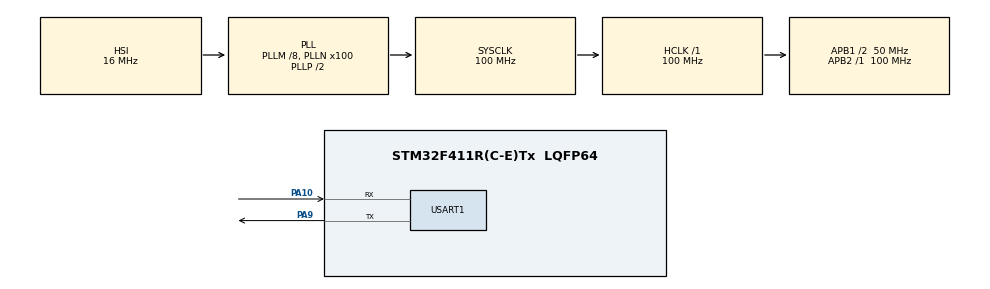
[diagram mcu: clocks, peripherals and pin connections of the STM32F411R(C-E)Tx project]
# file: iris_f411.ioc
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Mcu.Family=STM32F4
Mcu.Name=STM32F411R(C-E)Tx
Mcu.Package=LQFP64
NVIC.PriorityGroup=NVIC_PRIORITYGROUP_4
NVIC.USART1_IRQn=true\:0\:0\:false\:false\:true\:true\:true\:true
PA10.Mode=Asynchronous
PA10.Signal=USART1_RX
PA13.Mode=Serial_Wire
PA13.Signal=SYS_JTMS-SWDIO
PA14.Mode=Serial_Wire
PA14.Signal=SYS_JTCK-SWCLK
PA9.Mode=Asynchronous
PA9.Signal=USART1_TX
ProjectManager.HeapSize=0x800
ProjectManager.StackSize=0x800
ProjectManager.TargetToolchain=MDK-ARM V5.32
RCC.48MHZClocksFreq_Value=28571428.57142857
RCC.AHBFreq_Value=100000000
RCC.APB1CLKDivider=RCC_HCLK_DIV2
RCC.APB1Freq_Value=50000000
RCC.APB1TimFreq_Value=100000000
RCC.APB2Freq_Value=100000000
RCC.APB2TimFreq_Value=100000000
RCC.CortexFreq_Value=100000000
RCC.FLatency-AdvancedSettings=FLASH_LATENCY_3
RCC.HCLKFreq_Value=100000000
RCC.HSE_VALUE=25000000
RCC.HSI_VALUE=16000000
RCC.LSE_VALUE=32768
RCC.PLLM=8
RCC.PLLMUL=RCC_PLL_MUL9
RCC.PLLN=100
RCC.PLLQ=7
RCC.RCC_PLLsource_Clock_Source_FROM_HSE=RCC_HSE_PREDIV_DIV2
RCC.SYSCLKFreq_VALUE=100000000
RCC.SYSCLKSource=RCC_SYSCLKSOURCE_PLLCLK
RCC.SYSCLKSourceVirtual=RCC_SYSCLKSOURCE_PLLCLK
RCC.VCOOutputFreq_Value=200000000
STMicroelectronics.X-CUBE-AI.10.2.0.ActivationBufferSizeList=2052
STMicroelectronics.X-CUBE-AI.10.2.0.ActivationBuffers=pool0
STMicroelectronics.X-CUBE-AI.10.2.0.ActivationNames=pool0
STMicroelectronics.X-CUBE-AI.10.2.0.ActivationSizes=AI_NETWORK_DATA_ACTIVATION_1_SIZE
STMicroelectronics.X-CUBE-AI.10.2.0.ApplicationCcDeviceJjApplication=ApplicationTemplate
STMicroelectronics.X-CUBE-AI.10.2.0.HeapSize=0x800
STMicroelectronics.X-CUBE-AI.10.2.0.InternalRamActivationBufferMaxSize=AI_NETWORK_DATA_ACTIVATIONS_SIZE
STMicroelectronics.X-CUBE-AI.10.2.0.LatestDirectoryUsed-66b77b68632d567aa93bb05c56d0c70e0db3c44ed29e73d25cb62fc59ebfa969=D\:\\iris_stm32
STMicroelectronics.X-CUBE-AI.10.2.0.MaximumNumberOfInputLayer=1
STMicroelectronics.X-CUBE-AI.10.2.0.MaximumNumberOfOutputLayer=1
STMicroelectronics.X-CUBE-AI.10.2.0.MaximumSizeOfInputLayer=1
STMicroelectronics.X-CUBE-AI.10.2.0.MaximumSizeOfOutputLayer=1
STMicroelectronics.X-CUBE-AI.10.2.0.ModelActualCompression-66b77b68632d567aa93bb05c56d0c70e0db3c44ed29e73d25cb62fc59ebfa969=0.0
STMicroelectronics.X-CUBE-AI.10.2.0.ModelCompression-66b77b68632d567aa93bb05c56d0c70e0db3c44ed29e73d25cb62fc59ebfa969=None
STMicroelectronics.X-CUBE-AI.10.2.0.ModelFlashOccupation-66b77b68632d567aa93bb05c56d0c70e0db3c44ed29e73d25cb62fc59ebfa969=11440
STMicroelectronics.X-CUBE-AI.10.2.0.ModelHashList=66b77b68632d567aa93bb05c56d0c70e0db3c44ed29e73d25cb62fc59ebfa969
STMicroelectronics.X-CUBE-AI.10.2.0.ModelKind-66b77b68632d567aa93bb05c56d0c70e0db3c44ed29e73d25cb62fc59ebfa969=TFLITE
STMicroelectronics.X-CUBE-AI.10.2.0.ModelMacc-66b77b68632d567aa93bb05c56d0c70e0db3c44ed29e73d25cb62fc59ebfa969=200
STMicroelectronics.X-CUBE-AI.10.2.0.ModelName-66b77b68632d567aa93bb05c56d0c70e0db3c44ed29e73d25cb62fc59ebfa969=network
STMicroelectronics.X-CUBE-AI.10.2.0.ModelNameList=network
STMicroelectronics.X-CUBE-AI.10.2.0.ModelRamOccupation-66b77b68632d567aa93bb05c56d0c70e0db3c44ed29e73d25cb62fc59ebfa969=2052
STMicroelectronics.X-CUBE-AI.10.2.0.ModelStructureFile-66b77b68632d567aa93bb05c56d0c70e0db3c44ed29e73d25cb62fc59ebfa969=/D\:/iris_stm32/iris_model.tflite
STMicroelectronics.X-CUBE-AI.10.2.0.ModelType-66b77b68632d567aa93bb05c56d0c70e0db3c44ed29e73d25cb62fc59ebfa969=STM32Cube.AI MCU runtime
STMicroelectronics.X-CUBE-AI.10.2.0.ReadyForCodeGeneration=true
STMicroelectronics.X-CUBE-AI.10.2.0.StackSize=0x800
STMicroelectronics.X-CUBE-AI.10.2.0.WorkingBufferStartAddrList=0xFFFFFFFF
STMicroelectronics.X-CUBE-AI.10.2.0.XAaCUBEAaAICcArtificialOoIntelligenceJjCore=true
STMicroelectronics.X-CUBE-AI.10.2.0.copyWeightToRam=false
STMicroelectronics.X-CUBE-AI.10.2.0.customLayerConfigEnabled=false
STMicroelectronics.X-CUBE-AI.10.2.0.noOnnxIoTranspose=false
STMicroelectronics.X-CUBE-AI.10.2.0.useInputAllocation=true
STMicroelectronics.X-CUBE-AI.10.2.0.useOutputAllocation=true
USART1.VirtualMode=VM_ASYNC
VP_CRC_VS_CRC.Mode=CRC_Activate
VP_STMicroelectronics.X-CUBE-AI_VS_ArtificialOoIntelligenceJjXAaCUBEAaAI_10.2.0.Mode=ArtificialOoIntelligenceJjXAaCUBEAaAI
VP_STMicroelectronics.X-CUBE-AI_VS_DeviceJjApplication_10.2.0.Mode=DeviceJjApplication
board=custom

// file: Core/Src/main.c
/* USER CODE BEGIN Header */
/**
  ******************************************************************************
  * @file           : main.c
  * @brief          : Main program body
  ******************************************************************************
  * @attention
  *
  * Copyright (c) 2026 STMicroelectronics.
  * All rights reserved.
  *
  * This software is licensed under terms that can be found in the LICENSE file
  * in the root directory of this software component.
  * If no LICENSE file comes with this software, it is provided AS-IS.
  *
  ******************************************************************************
  */
/* USER CODE END Header */
#include "main.h"
#include "app_x-cube-ai.h"

/* USER CODE BEGIN Includes */
#include "iris_uart.h"
/* USER CODE END Includes */

CRC_HandleTypeDef hcrc;

UART_HandleTypeDef huart1;

void SystemClock_Config(void);
static void MX_GPIO_Init(void);
static void MX_CRC_Init(void);
static void MX_USART1_UART_Init(void);

int main(void)
{

  /* MCU Configuration--------------------------------------------------------*/

  /* Reset of all peripherals, Initializes the Flash interface and the Systick. */
  HAL_Init();

  /* Configure the system clock */
  SystemClock_Config();

  /* Initialize all configured peripherals */
  MX_GPIO_Init();
  MX_CRC_Init();
  MX_USART1_UART_Init();
  //MX_X_CUBE_AI_Init();
  /* USER CODE BEGIN 2 */
	IrisApp_Init();
  /* USER CODE END 2 */

  /* Infinite loop */
  while (1)
  {

  //MX_X_CUBE_AI_Process();
    /* USER CODE BEGIN 3 */
		IrisApp_Process();
  }
  /* USER CODE END 3 */
}

void SystemClock_Config(void)
{
  RCC_OscInitTypeDef RCC_OscInitStruct = {0};
  RCC_ClkInitTypeDef RCC_ClkInitStruct = {0};

  /** Configure the main internal regulator output voltage
  */
  __HAL_RCC_PWR_CLK_ENABLE();
  __HAL_PWR_VOLTAGESCALING_CONFIG(PWR_REGULATOR_VOLTAGE_SCALE1);

  /** Initializes the RCC Oscillators according to the specified parameters
  * in the RCC_OscInitTypeDef structure.
  */
  RCC_OscInitStruct.OscillatorType = RCC_OSCILLATORTYPE_HSI;
  RCC_OscInitStruct.HSIState = RCC_HSI_ON;
  RCC_OscInitStruct.HSICalibrationValue = RCC_HSICALIBRATION_DEFAULT;
  RCC_OscInitStruct.PLL.PLLState = RCC_PLL_ON;
  RCC_OscInitStruct.PLL.PLLSource = RCC_PLLSOURCE_HSI;
  RCC_OscInitStruct.PLL.PLLM = 8;
  RCC_OscInitStruct.PLL.PLLN = 100;
  RCC_OscInitStruct.PLL.PLLP = RCC_PLLP_DIV2;
  RCC_OscInitStruct.PLL.PLLQ = 7;
  if (HAL_RCC_OscConfig(&RCC_OscInitStruct) != HAL_OK)
  {
    Error_Handler();
  }

  /** Initializes the CPU, AHB and APB buses clocks
  */
  RCC_ClkInitStruct.ClockType = RCC_CLOCKTYPE_HCLK|RCC_CLOCKTYPE_SYSCLK
                              |RCC_CLOCKTYPE_PCLK1|RCC_CLOCKTYPE_PCLK2;
  RCC_ClkInitStruct.SYSCLKSource = RCC_SYSCLKSOURCE_PLLCLK;
  RCC_ClkInitStruct.AHBCLKDivider = RCC_SYSCLK_DIV1;
  RCC_ClkInitStruct.APB1CLKDivider = RCC_HCLK_DIV2;
  RCC_ClkInitStruct.APB2CLKDivider = RCC_HCLK_DIV1;

  if (HAL_RCC_ClockConfig(&RCC_ClkInitStruct, FLASH_LATENCY_3) != HAL_OK)
  {
    Error_Handler();
  }
}

static void MX_CRC_Init(void)
{

  hcrc.Instance = CRC;
  if (HAL_CRC_Init(&hcrc) != HAL_OK)
  {
    Error_Handler();
  }

}

static void MX_USART1_UART_Init(void)
{

  huart1.Instance = USART1;
  huart1.Init.BaudRate = 115200;
  huart1.Init.WordLength = UART_WORDLENGTH_8B;
  huart1.Init.StopBits = UART_STOPBITS_1;
  huart1.Init.Parity = UART_PARITY_NONE;
  huart1.Init.Mode = UART_MODE_TX_RX;
  huart1.Init.HwFlowCtl = UART_HWCONTROL_NONE;
  huart1.Init.OverSampling = UART_OVERSAMPLING_16;
  if (HAL_UART_Init(&huart1) != HAL_OK)
  {
    Error_Handler();
  }

}

static void MX_GPIO_Init(void)
{

  /* GPIO Ports Clock Enable */
  __HAL_RCC_GPIOA_CLK_ENABLE();

}

void Error_Handler(void)
{
  __disable_irq();
  while (1)
  {
  }
}
